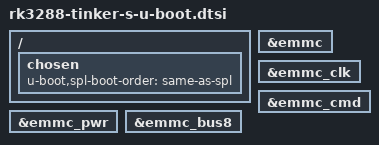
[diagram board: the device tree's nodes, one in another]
// SPDX-License-Identifier: GPL-2.0+
/*
 * Copyright (C) 2019 Amarula Solutions SRO
 */

#include "rk3288-u-boot.dtsi"
#include "rk3288-tinker-u-boot.dtsi"

/ {
	chosen {
		u-boot,spl-boot-order = \
			"same-as-spl", &sdmmc, &emmc;
	};
};

&emmc {
	bootph-pre-ram;
};

&emmc_clk {
	bootph-pre-ram;
};

&emmc_cmd {
	bootph-pre-ram;
};

&emmc_pwr {
	bootph-pre-ram;
};

&emmc_bus8 {
	bootph-pre-ram;
};
